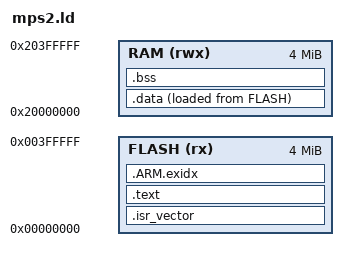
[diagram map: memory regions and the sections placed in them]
MEMORY
{
    FLASH (rx)  : ORIGIN = 0x00000000, LENGTH = 4M
    RAM   (rwx) : ORIGIN = 0x20000000, LENGTH = 4M
}
_estack = ORIGIN(RAM) + LENGTH(RAM);
ENTRY(Reset_Handler)
SECTIONS
{
    .isr_vector : { KEEP(*(.isr_vector)) } > FLASH
    .text : { *(.text*) *(.rodata*) } > FLASH
    .ARM.exidx : { *(.ARM.exidx*) } > FLASH
    _sidata = LOADADDR(.data);
    .data : { _sdata = .; *(.data*) _edata = .; } > RAM AT > FLASH
    .bss : { _sbss = .; *(.bss*) *(COMMON) _ebss = .; } > RAM
    PROVIDE(_end = .);
}
